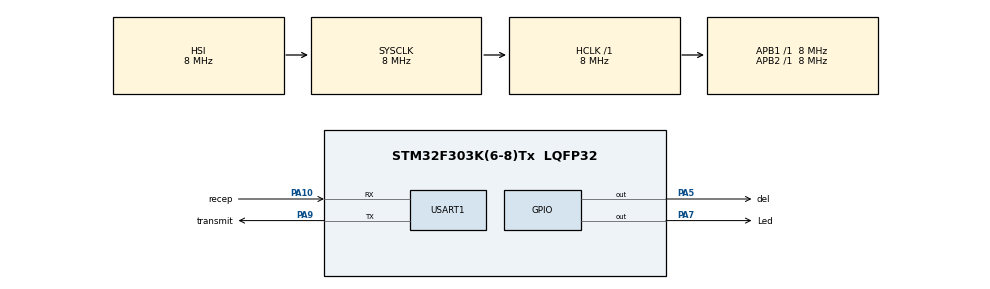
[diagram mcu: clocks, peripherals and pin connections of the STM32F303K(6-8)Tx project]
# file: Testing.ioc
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FREERTOS.Tasks01=defaultTask,0,128,StartDefaultTask,Default,NULL
Mcu.Family=STM32F3
Mcu.Name=STM32F303K(6-8)Tx
Mcu.Package=LQFP32
NVIC.PriorityGroup=NVIC_PRIORITYGROUP_4
PA10.GPIO_Label=recep
PA10.Mode=Asynchronous
PA10.Signal=USART1_RX
PA13.GPIO_Label=SWDIO
PA13.Signal=SYS_JTMS-SWDIO
PA14.GPIO_Label=SWCLK
PA14.Signal=SYS_JTCK-SWCLK
PA15.Signal=USART2_RX
PA2.Signal=USART2_TX
PA5.GPIO_Label=del
PA5.GPIO_ModeDefaultOutputPP=GPIO_MODE_OUTPUT_PP
PA5.Signal=GPIO_Output
PA7.GPIO_Label=Led
PA7.GPIO_ModeDefaultOutputPP=GPIO_MODE_OUTPUT_OD
PA7.Signal=GPIO_Output
PA9.GPIO_Label=transmit
PA9.Mode=Asynchronous
PA9.Signal=USART1_TX
PF0\ /\ OSC_IN.GPIO_Label=MCO
PF0\ /\ OSC_IN.Signal=RCC_OSC_IN
ProjectManager.HeapSize=0x200
ProjectManager.StackSize=0x400
ProjectManager.TargetToolchain=Makefile
RCC.AHBFreq_Value=8000000
RCC.APB1Freq_Value=8000000
RCC.APB2Freq_Value=8000000
RCC.CortexFreq_Value=8000000
RCC.HSE_VALUE=8000000
RCC.HSI_VALUE=8000000
RCC.SYSCLKFreq_VALUE=8000000
USART1.VirtualMode-Asynchronous=VM_ASYNC
VP_FREERTOS_VS_ENABLE.Mode=Enabled
board=NUCLEO-F303K8

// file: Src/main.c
/**
  ******************************************************************************
  * File Name          : main.c
  * Description        : Main program body
  ******************************************************************************
  * This notice applies to any and all portions of this file
  * that are not between comment pairs USER CODE BEGIN and
  * USER CODE END. Other portions of this file, whether
  * inserted by the user or by software development tools
  * are owned by their respective copyright owners.
  *
  * Copyright (c) 2017 STMicroelectronics International N.V.
  * All rights reserved.
  *
  * Redistribution and use in source and binary forms, with or without
  * modification, are permitted, provided that the following conditions are met:
  *
  * 1. Redistribution of source code must retain the above copyright notice,
  *    this list of conditions and the following disclaimer.
  * 2. Redistributions in binary form must reproduce the above copyright notice,
  *    this list of conditions and the following disclaimer in the documentation
  *    and/or other materials provided with the distribution.
  * 3. Neither the name of STMicroelectronics nor the names of other
  *    contributors to this software may be used to endorse or promote products
  *    derived from this software without specific written permission.
  * 4. This software, including modifications and/or derivative works of this
  *    software, must execute solely and exclusively on microcontroller or
  *    microprocessor devices manufactured by or for STMicroelectronics.
  * 5. Redistribution and use of this software other than as permitted under
  *    this license is void and will automatically terminate your rights under
  *    this license.
  *
  * THIS SOFTWARE IS PROVIDED BY STMICROELECTRONICS AND CONTRIBUTORS "AS IS"
  * AND ANY EXPRESS, IMPLIED OR STATUTORY WARRANTIES, INCLUDING, BUT NOT
  * LIMITED TO, THE IMPLIED WARRANTIES OF MERCHANTABILITY, FITNESS FOR A
  * PARTICULAR PURPOSE AND NON-INFRINGEMENT OF THIRD PARTY INTELLECTUAL PROPERTY
  * RIGHTS ARE DISCLAIMED TO THE FULLEST EXTENT PERMITTED BY LAW. IN NO EVENT
  * SHALL STMICROELECTRONICS OR CONTRIBUTORS BE LIABLE FOR ANY DIRECT, INDIRECT,
  * INCIDENTAL, SPECIAL, EXEMPLARY, OR CONSEQUENTIAL DAMAGES (INCLUDING, BUT NOT
  * LIMITED TO, PROCUREMENT OF SUBSTITUTE GOODS OR SERVICES; LOSS OF USE, DATA,
  * OR PROFITS; OR BUSINESS INTERRUPTION) HOWEVER CAUSED AND ON ANY THEORY OF
  * LIABILITY, WHETHER IN CONTRACT, STRICT LIABILITY, OR TORT (INCLUDING
  * NEGLIGENCE OR OTHERWISE) ARISING IN ANY WAY OUT OF THE USE OF THIS SOFTWARE,
  * EVEN IF ADVISED OF THE POSSIBILITY OF SUCH DAMAGE.
  *
  ******************************************************************************
  */
#include "main.h"
#include "stm32f3xx_hal.h"
#include "cmsis_os.h"

UART_HandleTypeDef huart1;

osThreadId defaultTaskHandle;

/* USER CODE BEGIN PV */
/* Private variables ---------------------------------------------------------*/

/* USER CODE END PV */

void SystemClock_Config(void);
static void MX_GPIO_Init(void);
static void MX_USART1_UART_Init(void);
void StartDefaultTask(void const * argument);

/* USER CODE BEGIN PFP */
/* Private function prototypes -----------------------------------------------*/

/* USER CODE END PFP */

int main(void)
{

  /* MCU Configuration----------------------------------------------------------*/

  /* Reset of all peripherals, Initializes the Flash interface and the Systick. */
  HAL_Init();

  /* Configure the system clock */
  SystemClock_Config();

  /* Initialize all configured peripherals */
  MX_GPIO_Init();
  MX_USART1_UART_Init();

  /* Create the thread(s) */
  /* definition and creation of defaultTask */
  osThreadDef(defaultTask, StartDefaultTask, osPriorityNormal, 0, 128);
  defaultTaskHandle = osThreadCreate(osThread(defaultTask), NULL);

  /* Start scheduler */
  osKernelStart();

  /* We should never get here as control is now taken by the scheduler */

  /* Infinite loop */
  while (1)
  {

  }

}

/** System Clock Configuration
*/
void SystemClock_Config(void)
{

  RCC_OscInitTypeDef RCC_OscInitStruct;
  RCC_ClkInitTypeDef RCC_ClkInitStruct;
  RCC_PeriphCLKInitTypeDef PeriphClkInit;

    /**Initializes the CPU, AHB and APB busses clocks
    */
  RCC_OscInitStruct.OscillatorType = RCC_OSCILLATORTYPE_HSI;
  RCC_OscInitStruct.HSIState = RCC_HSI_ON;
  RCC_OscInitStruct.HSICalibrationValue = 16;
  RCC_OscInitStruct.PLL.PLLState = RCC_PLL_NONE;
  if (HAL_RCC_OscConfig(&RCC_OscInitStruct) != HAL_OK)
  {
    _Error_Handler(__FILE__, __LINE__);
  }

    /**Initializes the CPU, AHB and APB busses clocks
    */
  RCC_ClkInitStruct.ClockType = RCC_CLOCKTYPE_HCLK|RCC_CLOCKTYPE_SYSCLK
                              |RCC_CLOCKTYPE_PCLK1|RCC_CLOCKTYPE_PCLK2;
  RCC_ClkInitStruct.SYSCLKSource = RCC_SYSCLKSOURCE_HSI;
  RCC_ClkInitStruct.AHBCLKDivider = RCC_SYSCLK_DIV1;
  RCC_ClkInitStruct.APB1CLKDivider = RCC_HCLK_DIV1;
  RCC_ClkInitStruct.APB2CLKDivider = RCC_HCLK_DIV1;

  if (HAL_RCC_ClockConfig(&RCC_ClkInitStruct, FLASH_LATENCY_0) != HAL_OK)
  {
    _Error_Handler(__FILE__, __LINE__);
  }

  PeriphClkInit.PeriphClockSelection = RCC_PERIPHCLK_USART1;
  PeriphClkInit.Usart1ClockSelection = RCC_USART1CLKSOURCE_PCLK1;
  if (HAL_RCCEx_PeriphCLKConfig(&PeriphClkInit) != HAL_OK)
  {
    _Error_Handler(__FILE__, __LINE__);
  }

    /**Configure the Systick interrupt time
    */
  HAL_SYSTICK_Config(HAL_RCC_GetHCLKFreq()/1000);

    /**Configure the Systick
    */
  HAL_SYSTICK_CLKSourceConfig(SYSTICK_CLKSOURCE_HCLK);

  /* SysTick_IRQn interrupt configuration */
  HAL_NVIC_SetPriority(SysTick_IRQn, 15, 0);
}

/* USART1 init function */
static void MX_USART1_UART_Init(void)
{

  huart1.Instance = USART1;
  huart1.Init.BaudRate = 38400;
  huart1.Init.WordLength = UART_WORDLENGTH_7B;
  huart1.Init.StopBits = UART_STOPBITS_1;
  huart1.Init.Parity = UART_PARITY_NONE;
  huart1.Init.Mode = UART_MODE_TX_RX;
  huart1.Init.HwFlowCtl = UART_HWCONTROL_NONE;
  huart1.Init.OverSampling = UART_OVERSAMPLING_16;
  huart1.Init.OneBitSampling = UART_ONE_BIT_SAMPLE_DISABLE;
  huart1.AdvancedInit.AdvFeatureInit = UART_ADVFEATURE_NO_INIT;
  if (HAL_UART_Init(&huart1) != HAL_OK)
  {
    _Error_Handler(__FILE__, __LINE__);
  }

}

/** Configure pins as
        * Analog
        * Input
        * Output
        * EVENT_OUT
        * EXTI
     PA2   ------> USART2_TX
     PA15   ------> USART2_RX
*/
static void MX_GPIO_Init(void)
{

  GPIO_InitTypeDef GPIO_InitStruct;

  /* GPIO Ports Clock Enable */
  __HAL_RCC_GPIOF_CLK_ENABLE();
  __HAL_RCC_GPIOA_CLK_ENABLE();

  /*Configure GPIO pin Output Level */
  HAL_GPIO_WritePin(GPIOA, del_Pin|Led_Pin, GPIO_PIN_RESET);

  /*Configure GPIO pins : PA2 PA15 */
  GPIO_InitStruct.Pin = GPIO_PIN_2|GPIO_PIN_15;
  GPIO_InitStruct.Mode = GPIO_MODE_AF_PP;
  GPIO_InitStruct.Pull = GPIO_NOPULL;
  GPIO_InitStruct.Speed = GPIO_SPEED_FREQ_HIGH;
  GPIO_InitStruct.Alternate = GPIO_AF7_USART2;
  HAL_GPIO_Init(GPIOA, &GPIO_InitStruct);

  /*Configure GPIO pin : del_Pin */
  GPIO_InitStruct.Pin = del_Pin;
  GPIO_InitStruct.Mode = GPIO_MODE_OUTPUT_PP;
  GPIO_InitStruct.Pull = GPIO_NOPULL;
  GPIO_InitStruct.Speed = GPIO_SPEED_FREQ_LOW;
  HAL_GPIO_Init(del_GPIO_Port, &GPIO_InitStruct);

  /*Configure GPIO pin : Led_Pin */
  GPIO_InitStruct.Pin = Led_Pin;
  GPIO_InitStruct.Mode = GPIO_MODE_OUTPUT_OD;
  GPIO_InitStruct.Pull = GPIO_NOPULL;
  GPIO_InitStruct.Speed = GPIO_SPEED_FREQ_LOW;
  HAL_GPIO_Init(Led_GPIO_Port, &GPIO_InitStruct);

}

/* StartDefaultTask function */
void StartDefaultTask(void const * argument)
{
    for(;;)
  {
  }
}
void _Error_Handler(char * file, int line)
{
  while(1)
  {
  }
}

/************************ (C) COPYRIGHT STMicroelectronics *****END OF FILE****/

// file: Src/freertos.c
/**
  ******************************************************************************
  * File Name          : freertos.c
  * Description        : Code for freertos applications
  ******************************************************************************
  * This notice applies to any and all portions of this file
  * that are not between comment pairs USER CODE BEGIN and
  * USER CODE END. Other portions of this file, whether
  * inserted by the user or by software development tools
  * are owned by their respective copyright owners.
  *
  * Copyright (c) 2017 STMicroelectronics International N.V.
  * All rights reserved.
  *
  * Redistribution and use in source and binary forms, with or without
  * modification, are permitted, provided that the following conditions are met:
  *
  * 1. Redistribution of source code must retain the above copyright notice,
  *    this list of conditions and the following disclaimer.
  * 2. Redistributions in binary form must reproduce the above copyright notice,
  *    this list of conditions and the following disclaimer in the documentation
  *    and/or other materials provided with the distribution.
  * 3. Neither the name of STMicroelectronics nor the names of other
  *    contributors to this software may be used to endorse or promote products
  *    derived from this software without specific written permission.
  * 4. This software, including modifications and/or derivative works of this
  *    software, must execute solely and exclusively on microcontroller or
  *    microprocessor devices manufactured by or for STMicroelectronics.
  * 5. Redistribution and use of this software other than as permitted under
  *    this license is void and will automatically terminate your rights under
  *    this license.
  *
  * THIS SOFTWARE IS PROVIDED BY STMICROELECTRONICS AND CONTRIBUTORS "AS IS"
  * AND ANY EXPRESS, IMPLIED OR STATUTORY WARRANTIES, INCLUDING, BUT NOT
  * LIMITED TO, THE IMPLIED WARRANTIES OF MERCHANTABILITY, FITNESS FOR A
  * PARTICULAR PURPOSE AND NON-INFRINGEMENT OF THIRD PARTY INTELLECTUAL PROPERTY
  * RIGHTS ARE DISCLAIMED TO THE FULLEST EXTENT PERMITTED BY LAW. IN NO EVENT
  * SHALL STMICROELECTRONICS OR CONTRIBUTORS BE LIABLE FOR ANY DIRECT, INDIRECT,
  * INCIDENTAL, SPECIAL, EXEMPLARY, OR CONSEQUENTIAL DAMAGES (INCLUDING, BUT NOT
  * LIMITED TO, PROCUREMENT OF SUBSTITUTE GOODS OR SERVICES; LOSS OF USE, DATA,
  * OR PROFITS; OR BUSINESS INTERRUPTION) HOWEVER CAUSED AND ON ANY THEORY OF
  * LIABILITY, WHETHER IN CONTRACT, STRICT LIABILITY, OR TORT (INCLUDING
  * NEGLIGENCE OR OTHERWISE) ARISING IN ANY WAY OUT OF THE USE OF THIS SOFTWARE,
  * EVEN IF ADVISED OF THE POSSIBILITY OF SUCH DAMAGE.
  *
  ******************************************************************************
  */

#include "FreeRTOS.h"
#include "task.h"
#include <time.h>
#include <stdlib.h>

/* USER CODE BEGIN Includes */
#include "main.h"
#include "stm32f3xx_hal.h"
#include "cmsis_os.h"

UART_HandleTypeDef huart1;

osThreadId defaultTaskHandle;
/* USER CODE END Includes */

void EnvoiMessage(uint8_t data){
      uint8_t eun, b, edeux, equatre, ehuit,eseize, etrentedeux, esoixantequatre, ecentvingthuit, k, z;

      eun = (data & 0x01);
      edeux = (data & 0x02)/2;
      equatre =(data & 0x04)/4;
      ehuit = (data & 0x08)/8;
     eseize = (data & 0x10)/16;
      etrentedeux = (data & 0x20)/32;
      esoixantequatre = (data & 0x40)/64;
      ecentvingthuit = (data & 0x80)/128;

     b =  (ecentvingthuit^etrentedeux)*32 + (ecentvingthuit^esoixantequatre)*16 + (esoixantequatre^etrentedeux)*8 +ecentvingthuit*4 + esoixantequatre*2 + etrentedeux;
     k = (eseize^equatre)*32 +  (eseize^ehuit)*16 + (ehuit^equatre)*8 + eseize*4  + ehuit*2 + equatre;
     z = (0^eun)*32 + (0^edeux)*16 + (eun^edeux)*8 +edeux*2  + eun;

     HAL_UART_Transmit(&huart1, &b, sizeof(data), 0xEEEE);
     osDelay(2);
     HAL_UART_Transmit(&huart1, &k, sizeof(data), 0xEEEE);
     osDelay(2);
     HAL_UART_Transmit(&huart1, &z, sizeof(data), 0xEEEE);
     osDelay(2);

}

int ReceptionMessage(){
   uint8_t r, m, n, v, run, rdeux, rquatre, rhuit, rseize, rtrentedeux, ok, i;
   uint8_t rec[3];
   HAL_UART_Receive(&huart1, &r, sizeof(uint8_t), 0xEEEE);
   HAL_UART_Receive(&huart1, &m, sizeof(uint8_t), 0xEEEE);
   HAL_UART_Receive(&huart1, &n, sizeof(uint8_t), 0xEEEE);

   rec[0] = r;
   rec[1] = m;
   rec[2] = n;
   ok = 1;
    for (i =0; i<3; i++){
    run = (rec[i] & 0x01);
    rdeux = (rec[i] & 0x02)/2;
    rquatre =(rec[i] & 0x04)/4;
    rhuit = (rec[i] & 0x08)/8;
    rseize = (rec[i] & 0x10)/16;
    rtrentedeux = (rec[i] & 0x20)/32;
   if ((run^rdeux) != rhuit) ok =0;
   if ((rdeux^rquatre) != rseize) ok =0;
   if ((rquatre^run) != rtrentedeux) ok = 0;

}
r =  (r & 0x07)*32;
 m =  (m & 0x07)*4;
  n =  (n & 0x07);
v =  r + m + n;
if (ok == 1){
    for(int i = 0; i<5; i++){
    HAL_GPIO_TogglePin(GPIOB, GPIO_PIN_6);
    osDelay(500);}
  return(v);
}

else
    return(0);

}

   int recoitpos(){
       uint8_t a, x, y, c;
       uint8_t tb[3];
       a = ReceptionMessage();
       tab[0] = a & 0xF0;
       tab[1] = a & 0x0F;
       tab[2] = ReceptionMessage();
       return(tb);

   }
   void envoipos(uint8_t x, uint8_t y, uint8_t c){
            x = x*16 + y;
        EnvoiMessage(x);
        EnvoiMessage(c);

   }
   void Traduction(uint8_t msg){
       if (msg == 0x05){
          /*  envoipos(/* TI-BEAU MET TA FONTION CALCUL DE POS );*/
           }

       if (msg == 0x06){

       }
       if (msg == 0x07){
           if (/*capteurs ok*/){
           /*Fonction pour aller en haut*/
           ok();}
           else Non();
       }
       if (msg == 0x08){
           if (/*capteurs ok*/){
           /*Fonction pour aller en bas*/
           ok();}
           else Non();
       }
       if (msg == 0x09){
           if (/*capteurs ok*/){
           /*Fonction pour aller à Droite*/
           ok();}
           else Non();
       }
       if (msg == 0x0A){
           if (/*capteurs ok*/){
           /*Fonction pour aller à Gauche*/
           ok();}
           else Non();
       }
       if (msg == 0x0B){
     }
       if (msg == 0x0C){
       }
       if (msg == 0x0D){
           uint8_t a;
           srand(time(NULL));
           a = rand()%100;
           EnvoiMessage(a);
      }
       if (msg == 0x10){
   }
       if (msg == 0x11){
       }
       if (msg == 0x12){
   }
       if (msg == 0x13){
       }
  }
  void WaitFor(uint8_t z){
        while (z != ReceptionMessage()) ;
   }

   int TaPosition(){
       EnvoiMessage(0x05);
       return (recoitpos());
   }
   void ok(){
       EnvoiMessage(0x06);
   }
   void Monte(){
       EnvoiMessage(0x07);
       WaitFor(0x06);
   }
   void Descend(){
       EnvoiMessage(0x08);
       WaitFor(0x06);
   }
   void Droite(){
       EnvoiMessage(0x09);
       WaitFor(0x06);
   }
   void Gauche(){
       EnvoiMessage(0x0A);
       WaitFor(0x06);
   }
   void DansUnCoin(){
       EnvoiMessage(0x0B);
   }
   void Trouve(){

       EnvoiMessage(0x0C);
   }
   void Random(){int a, p;
       EnvoiMessage(0x0D);
       srand(time(NULL));
       a = rand()%256;
       if (ReceptionMessage() < a) {p = 1; EnvoiMessage(0x50);}
       else {p=0; EnvoiMessage(0x67);}}
   void Non(){EnvoiMessage(0x10);}
   void MemeCase(){
       EnvoiMessage(0x12);
   }
   void TuEsCoin(){
       EnvoiMessage(0x13);
   }

/* Hook prototypes */

/************************ (C) COPYRIGHT STMicroelectronics *****END OF FILE****/
